# MIMXRT685S_cm33 register map
Vendor: nxp.com; File version: 1.0
CPU: CM33 r2p0, little endian, MPU, FPU, VTOR, 3 interrupt priority bits
Registers are 32-bit, read-write, reset 0x0 unless marked. A register's access mark holds for its fields unless they carry their own. Offsets are from the block's base; [hi:lo] are bit positions; lines under a group give offsets from that group; {n}, {i} and the like mark numbered series.

## DMA0 — LPC-Next0 DMA controller
Base 0x40104000
Same registers: DMA1 0x40105000
0x00 CTRL — DMA control.
  [0] ENABLE — DMA controller master enable.
    0=DISABLED (Disabled. The DMA controller is disabled. This clears any triggers that were asserted at the point when disabled, but does not prevent re-triggering when the DMA controller is re-enabled.); 1=ENABLED (Enabled. The DMA controller is enabled.)
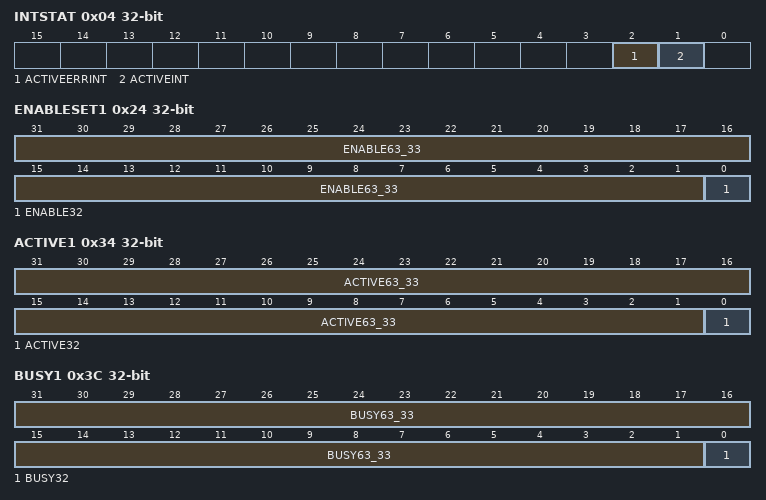
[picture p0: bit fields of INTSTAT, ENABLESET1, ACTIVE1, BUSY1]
0x04 INTSTAT ro — Interrupt status.
  [2] ACTIVEERRINT — Summarizes whether any error interrupts are pending.
    0=NOT_PENDING (Not pending. No error interrupts are pending.); 1=PENDING (Pending. At least one error interrupt is pending.)
  [1] ACTIVEINT — Summarizes whether any enabled interrupts (other than error interrupts) are pending.
    0=NOT_PENDING (Not pending. No enabled interrupts are pending.); 1=PENDING (Pending. At least one enabled interrupt is pending.)
0x08 SRAMBASE — SRAM address of the channel configuration table.
  [31:9] OFFSET — Address bits 31:9 of the beginning of the DMA descriptor table. For 18 channels, the table must begin on a 512 byte boundary.
0x20 ENABLESET0 — Channel Enable read and Set for all DMA channels.
  [31:0] ENA — Enable for DMA channel 0
    0=DISABLED (DMAchannel 0 is disabled.); 1=ENABLED (DMAchannel 0 is enabled.)
0x24 ENABLESET1 — Channel Enable read and Set for all DMA channels.
  [31:1] ENABLE63_33 — Additional enables for remaining DMA channels in the range 63 to 33.
    0=DISABLED (The relevant DMA channel is disabled.); 1=ENABLED (The relevant DMA channel is enabled.)
  [0] ENABLE32 — Enable for DMA channel 32
    0=DISABLED (DMAchannel 32 is disabled.); 1=ENABLED (DMAchannel 32 is enabled.)
0x28 ENABLECLR0 wo reset not defined — Channel Enable Clear for all DMA channels.
  [31:0] CLR — Writing ones to this register clears the corresponding bits in ENABLESET0.
0x2C ENABLECLR1 wo reset not defined — Channel Enable Clear for all DMA channels.
  [31:0] CLR — Writing ones to this register clears the corresponding bits in ENABLESET1.
0x30 ACTIVE0 ro — Channel Active status for all DMA channels.
  [31:0] ACT — Active flag for DMA channel 0.
    0=NOT_ACTIVE (DMAchannel 0 is not active.); 1=ACTIVE (DMAchannel 0 is active.)
0x34 ACTIVE1 ro — Channel Active status for all DMA channels.
  [31:1] ACTIVE63_33 — Additional Active flags for remaining DMA channels in the range 63 to 33. Any bits above the actually implemented channels are reserved.
    0=NOT_ACTIVE (The relevant DMA channel is not active.); 1=ACTIVE (The relevant DMA channel is active.)
  [0] ACTIVE32 — Active flag for DMA channel 32.
    0=NOT_ACTIVE (DMAchannel 32 is not active.); 1=ACTIVE (DMAchannel 32 is active.)
0x38 BUSY0 ro — Channel Busy status for all DMA channels.
  [31:0] BSY — Busy flag for DMA channel 0.
    0=NOT_BUSY (DMAchannel 0 is not busy.); 1=BUSY (DMAchannel 0 is busy.)
0x3C BUSY1 ro — Channel Busy status for all DMA channels.
  [31:1] BUSY63_33 — Additional Active flags for remaining DMA channels in the range 63 to 33. Any bits above the actually implemented channels are reserved.
    0=NOT_BUSY (The relevant DMA channel is not busy.); 1=BUSY (The relevant DMA channel is busy.)
  [0] BUSY32 — Busy flag for DMA channel 32.
    0=NOT_BUSY (DMAchannel 32 is not busy.); 1=BUSY (DMAchannel 0 is busy.)
0x40 ERRINT0 — Error Interrupt status for all DMA channels.
  [31:0] ERR — Error Interrupt flag for DMA channel 0.
    0=NOT_ACTIVE (The Error Interrupt is not active for DMA channel 0.); 1=PENDING (The Error Interrupt is pending for DMA channel 0.)
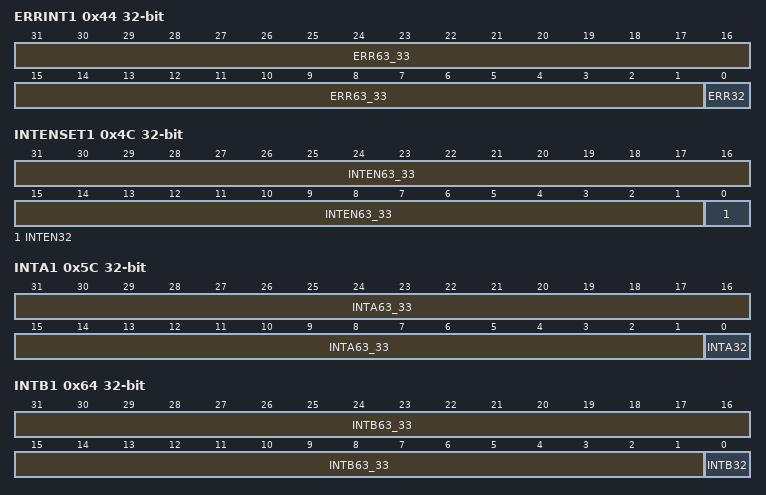
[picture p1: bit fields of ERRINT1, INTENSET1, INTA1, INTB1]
0x44 ERRINT1 — Error Interrupt status for all DMA channels.
  [31:1] ERR63_33 — Additional error Interrupt flags for remaining DMA channels in the range 63 to 33. Any bits above the actually implemented channels are reserved.
    0=NOT_ACTIVE (The Error Interrupt is not active for the relevant DMA channel.); 1=PENDING (The Error Interrupt is pending for the relevant DMA channel.)
  [0] ERR32 — Error Interrupt flag for DMA channel 32.
    0=NOT_ACTIVE (The Error Interrupt is not active for DMA channel 32.); 1=PENDING (The Error Interrupt is pending for DMA channel 32.)
0x48 INTENSET0 — Interrupt Enable read and Set for all DMA channels.
  [31:0] INTEN — Interrupt Enable read and set for DMA channel 0.
    0=DISABLED (The Interrupt for DMA channel 0 is disabled.); 1=ENABLED (The Interrupt for DMA channel 0 is enabled.)
0x4C INTENSET1 — Interrupt Enable read and Set for all DMA channels.
  [31:1] INTEN63_33 — Additional Interrupt Enable read and set bits for remaining DMA channels in the range 63 to 33. Any bits above the actually implemented channels are reserved.
    0=DISABLED (The Interrupt for the relevant DMA channel is disabled.); 1=ENABLED (The Interrupt for the relevant DMA channel is enabled.)
  [0] INTEN32 — Interrupt Enable read and set for DMA channel 32.
    0=DISABLED (The Interrupt for DMA channel 32 is disabled.); 1=ENABLED (The Interrupt for DMA channel 32 is enabled.)
0x50 INTENCLR0 wo reset not defined — Interrupt Enable Clear for all DMA channels.
  [31:0] CLR — Writing ones to this register clears corresponding bits in the DMAIntEnSet0.
0x54 INTENCLR1 wo reset not defined — Interrupt Enable Clear for all DMA channels.
  [31:0] CLR — Writing ones to this register clears corresponding bits in the DMAIntEnSet1.
0x58 INTA0 — Interrupt A status for all DMA channels.
  [31:0] IA — Interrupt A status for DMA channel 0.
    0=NOT_ACTIVE (The DMAchannel 0 interrupt A is not active.); 1=ACTIVE (The DMAchannel 0 interrupt A is active.)
0x5C INTA1 — Interrupt A status for all DMA channels.
  [31:1] INTA63_33 — Additional Interrupt A status bits for remaining DMA channels in the range 63 to 33. Any bits above the actually implemented channels are reserved.
    0=NOT_ACTIVE (Interrupt A is not active for the relevant DMA channel.); 1=ACTIVE (Interrupt A is active for the relevant DMA channel.)
  [0] INTA32 — Interrupt A status for DMA channel 32.
    0=NOT_ACTIVE (The DMAchannel 32 interrupt A is not active.); 1=ACTIVE (The DMAchannel 0 interrupt A is active.)
0x60 INTB0 — Interrupt B status for all DMA channels.
  [31:0] IB — Interrupt B status for DMA channel 0.
    0=NOT_ACTIVE (The DMAchannel 0 interrupt B is not active.); 1=ACTIVE (The DMAchannel 0 interrupt B is active.)
0x64 INTB1 — Interrupt B status for all DMA channels.
  [31:1] INTB63_33 — Additional Interrupt B status bits for remaining DMA channels in the range 63 to 33. Any bits above the actually implemented channels are reserved.
    0=NOT_ACTIVE (Interrupt B is not active for the relevant DMA channel.); 1=ACTIVE (Interrupt B is active for the relevant DMA channel.)
  [0] INTB32 — Interrupt B status for DMA channel 32.
    0=NOT_ACTIVE (The DMAchannel 32 interrupt B is not active.); 1=ACTIVE (The DMAchannel 32 interrupt B is active.)
0x68 SETVALID0 wo reset not defined — Set ValidPending control bits for all DMA channels.
  [31:0] SV — SetValid control for DMA channel 0.
    0=NO_EFFECT; 1=EFFECT (Sets the ValidPending control bit for DMA channel 0.)
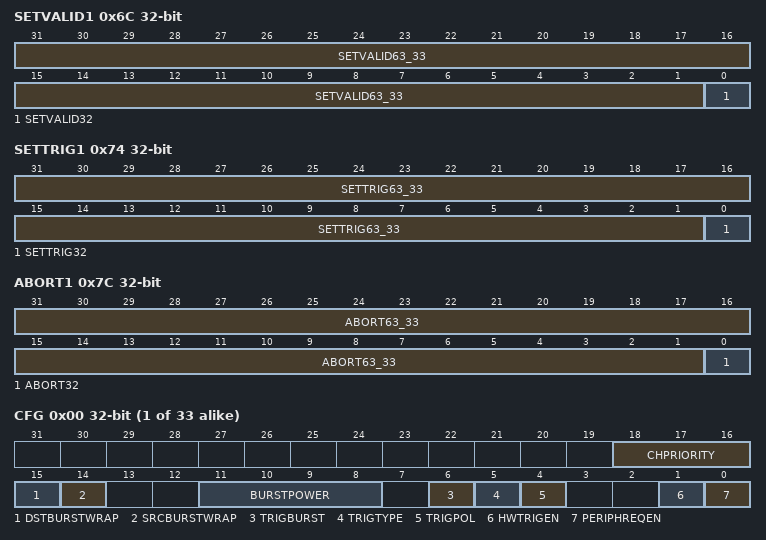
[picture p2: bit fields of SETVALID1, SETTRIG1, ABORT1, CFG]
0x6C SETVALID1 wo reset not defined — Set ValidPending control bits for all DMA channels.
  [31:1] SETVALID63_33 — Additional SetValid controls for remaining DMA channels in the range 63 to 33. Any bits above the actually implemented channels are reserved.
    0=NO_EFFECT; 1=EFFECT (Sets the ValidPending control bit for the relevant DMA channel.)
  [0] SETVALID32 — SetValid control for DMA channel 32.
    0=NO_EFFECT; 1=EFFECT (Sets the ValidPending control bit for DMA channel 32.)
0x70 SETTRIG0 wo reset not defined — Set Trigger control bits for all DMA channels.
  [31:0] TRIG — Set Trigger control bit for DMA channel 0.
    0=NO_EFFECT; 1=EFFECT (Sets the Trig bit for DMA channel 0.)
0x74 SETTRIG1 wo reset not defined — Set Trigger control bits for all DMA channels.
  [31:1] SETTRIG63_33 — Additional Set Trigger control bits for remaining DMA channels in the range 63 to 33. Any bits above the actually implemented channels are reserved.
    0=NO_EFFECT; 1=EFFECT (Sets the Trig bit for DMA channel for the relevant DMA channel.)
  [0] SETTRIG32 — Set Trigger control bit for DMA channel 32.
    0=NO_EFFECT; 1=EFFECT (Sets the Trig bit for DMA channel 32.)
0x78 ABORT0 wo reset not defined — Channel Abort control for all DMA channels.
  [31:0] ABORTCTRL — Abort control for DMA channel 0.
    0=NO_EFFECT; 1=EFFECT (Aborts DMA operations on channel 0.)
0x7C ABORT1 wo reset not defined — Channel Abort control for all DMA channels.
  [31:1] ABORT63_33 — Additional Abort controls for remaining DMA channels in the range 63 to 33. Any bits above the actually implemented channels are reserved.
    0=NO_EFFECT; 1=EFFECT (Aborts DMA operations on the relevant channel.)
  [0] ABORT32 — Abort control for DMA channel 32.
    0=NO_EFFECT; 1=EFFECT (Aborts DMA operations on channel 32.)
{0x400+0x10*i} CHANNEL[{i}] (i=0..32) group
  0x00 CFG — Configuration register for DMA channel .
    [18:16] CHPRIORITY — Priority of this channel when multiple DMA requests are pending. Eight priority levels are supported: 0x0 = highest priority. 0x7 = lowest priority.
    [15] DSTBURSTWRAP — Destination Burst Wrap. When enabled, the destination data address for the DMA is 'wrapped', meaning that the destination address range for each burst will be the same. As an example, this could be used to write several sequential registers to a peripheral for each DMA burst, writing the same registers again for each burst.
      0=DISABLED (Disabled. Destination burst wrapping is not enabled for this DMA channel.); 1=ENABLED (Enabled. Destination burst wrapping is enabled for this DMA channel.)
    [14] SRCBURSTWRAP — Source Burst Wrap. When enabled, the source data address for the DMA is 'wrapped', meaning that the source address range for each burst will be the same. As an example, this could be used to read several sequential registers from a peripheral for each DMA burst, reading the same registers again for each burst.
      0=DISABLED (Disabled. Source burst wrapping is not enabled for this DMA channel.); 1=ENABLED (Enabled. Source burst wrapping is enabled for this DMA channel.)
    [11:8] BURSTPOWER — Burst Power is used in two ways. It always selects the address wrap size when SRCBURSTWRAP and/or DSTBURSTWRAP modes are selected (see descriptions elsewhere in this register). When the TRIGBURST field elsewhere in this register = 1, Burst Power selects how many transfers are performed for each DMA trigger. This can be used, for example, with peripherals that contain a FIFO that can initiate a DMA operation when the FIFO reaches a certain level. 0000: Burst size = 1 (20). 0001: Burst size = 2 (21). 0010: Burst size = 4 (22). 1010: Burst size = 1024 (210). This corresponds to the maximum supported transfer count. others: not supported. The total transfer length as defined in the XFERCOUNT bits in the XFERCFG register must be an even multiple of the burst size.
    [6] TRIGBURST — Trigger Burst. Selects whether hardware triggers cause a single or burst transfer.
      0=SINGLE (Single transfer. Hardware trigger causes a single transfer.); 1=BURST (Burst transfer. When the trigger for this channel is set to edge triggered, a hardware trigger causes a burst transfer, as defined by BURSTPOWER. When the trigger for this channel is set to level triggered, a hardware trigger causes transfers to continue as long as the trigger is asserted, unless the transfer is complete.)
    [5] TRIGTYPE — Trigger Type. Selects hardware trigger as edge triggered or level triggered.
      0=EDGE (Edge. Hardware trigger is edge triggered. Transfers will be initiated and completed, as specified for a single trigger.); 1=LEVEL (Level. Hardware trigger is level triggered. Note that when level triggering without burst (BURSTPOWER = 0) is selected, only hardware triggers should be used on that channel. Transfers continue as long as the trigger level is asserted. Once the trigger is de-asserted, the transfer will be paused until the trigger is, again, asserted. However, the transfer will not be paused until any remaining transfers within the current BURSTPOWER length are completed.)
    [4] TRIGPOL — Trigger Polarity. Selects the polarity of a hardware trigger for this channel.
      0=ACTIVE_LOW_FALLING (Active low - falling edge. Hardware trigger is active low or falling edge triggered, based on TRIGTYPE.); 1=ACTIVE_HIGH_RISING (Active high - rising edge. Hardware trigger is active high or rising edge triggered, based on TRIGTYPE.)
    [1] HWTRIGEN — Hardware Triggering Enable for this channel.
      0=DISABLED (Disabled. Hardware triggering is not used.); 1=ENABLED (Enabled. Use hardware triggering.)
    [0] PERIPHREQEN — Peripheral request Enable. If a DMA channel is used to perform a memory-to-memory move, any peripheral DMA request associated with that channel can be disabled to prevent any interaction between the peripheral and the DMA controller.
      0=DISABLED (Disabled. Peripheral DMA requests are disabled.); 1=ENABLED (Enabled. Peripheral DMA requests are enabled.)
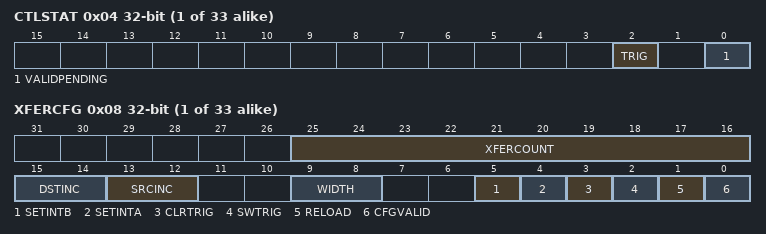
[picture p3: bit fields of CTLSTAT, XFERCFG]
  0x04 CTLSTAT ro — Control and status register for DMA channel .
    [2] TRIG — Trigger flag. Indicates that the trigger for this channel is currently set. This bit is cleared at the end of an entire transfer or upon reload when CLRTRIG = 1.
      0=NOT_TRIGGERED (Not triggered. The trigger for this DMA channel is not set. DMA operations will not be carried out.); 1=TRIGGERED (Triggered. The trigger for this DMA channel is set. DMA operations will be carried out.)
    [0] VALIDPENDING — Valid pending flag for this channel. This bit is set when a 1 is written to the corresponding bit in the related SETVALID register when CFGVALID = 1 for the same channel.
      0=NO_EFFECT (No effect. No effect on DMA operation.); 1=VALID_PENDING
  0x08 XFERCFG — Transfer configuration register for DMA channel .
    [25:16] XFERCOUNT — Total number of transfers to be performed, minus 1 encoded. The number of bytes transferred is: (XFERCOUNT + 1) x data width (as defined by the WIDTH field). The DMA controller uses this bit field during transfer to count down. Hence, it cannot be used by software to read back the size of the transfer, for instance, in an interrupt handler. 0x0 = a total of 1 transfer will be performed. 0x1 = a total of 2 transfers will be performed. 0x3FF = a total of 1,024 transfers will be performed.
    [15:14] DSTINC — Determines whether the destination address is incremented for each DMA transfer.
      0=NO_INCREMENT (No increment. The destination address is not incremented for each transfer. This is the usual case when the destination is a peripheral device.); 1=WIDTH_X_1 (1 x width. The destination address is incremented by the amount specified by Width for each transfer. This is the usual case when the destination is memory.); 2=WIDTH_X_2 (2 x width. The destination address is incremented by 2 times the amount specified by Width for each transfer.); 3=WIDTH_X_4 (4 x width. The destination address is incremented by 4 times the amount specified by Width for each transfer.)
    [13:12] SRCINC — Determines whether the source address is incremented for each DMA transfer.
      0=NO_INCREMENT (No increment. The source address is not incremented for each transfer. This is the usual case when the source is a peripheral device.); 1=WIDTH_X_1 (1 x width. The source address is incremented by the amount specified by Width for each transfer. This is the usual case when the source is memory.); 2=WIDTH_X_2 (2 x width. The source address is incremented by 2 times the amount specified by Width for each transfer.); 3=WIDTH_X_4 (4 x width. The source address is incremented by 4 times the amount specified by Width for each transfer.)
    [9:8] WIDTH — Transfer width used for this DMA channel.
      0=BIT_8 (8-bit. 8-bit transfers are performed (8-bit source reads and destination writes).); 1=BIT_16 (16-bit. 6-bit transfers are performed (16-bit source reads and destination writes).); 2=BIT_32 (32-bit. 32-bit transfers are performed (32-bit source reads and destination writes).)
    [5] SETINTB — Set Interrupt flag B for this channel. There is no hardware distinction between interrupt A and B. They can be used by software to assist with more complex descriptor usage. By convention, interrupt A may be used when only one interrupt flag is needed.
      0=NO_EFFECT; 1=SET (Set. The INTB flag for this channel will be set when the current descriptor is exhausted.)
    [4] SETINTA — Set Interrupt flag A for this channel. There is no hardware distinction between interrupt A and B. They can be used by software to assist with more complex descriptor usage. By convention, interrupt A may be used when only one interrupt flag is needed.
      0=NO_EFFECT; 1=SET (Set. The INTA flag for this channel will be set when the current descriptor is exhausted.)
    [3] CLRTRIG — Clear Trigger.
      0=NOT_CLEARED (Not cleared. The trigger is not cleared when this descriptor is exhausted. If there is a reload, the next descriptor will be started.); 1=CLEARED (Cleared. The trigger is cleared when this descriptor is exhausted)
    [2] SWTRIG — Software Trigger.
      0=NOT_SET (Not set. When written by software, the trigger for this channel is not set. A new trigger, as defined by the HWTRIGEN, TRIGPOL, and TRIGTYPE will be needed to start the channel.); 1=SET (Set. When written by software, the trigger for this channel is set immediately. This feature should not be used with level triggering when TRIGBURST = 0.)
    [1] RELOAD — Indicates whether the channel's control structure will be reloaded when the current descriptor is exhausted. Reloading allows ping-pong and linked transfers.
      0=DISABLED (Disabled. Do not reload the channels' control structure when the current descriptor is exhausted.); 1=ENABLED (Enabled. Reload the channels' control structure when the current descriptor is exhausted.)
    [0] CFGVALID — Configuration Valid flag. This bit indicates whether the current channel descriptor is valid and can potentially be acted upon, if all other activation criteria are fulfilled.
      0=NOT_VALID (Not valid. The channel descriptor is not considered valid until validated by an associated SETVALID0 setting.); 1=VALID (Valid. The current channel descriptor is considered valid.)
